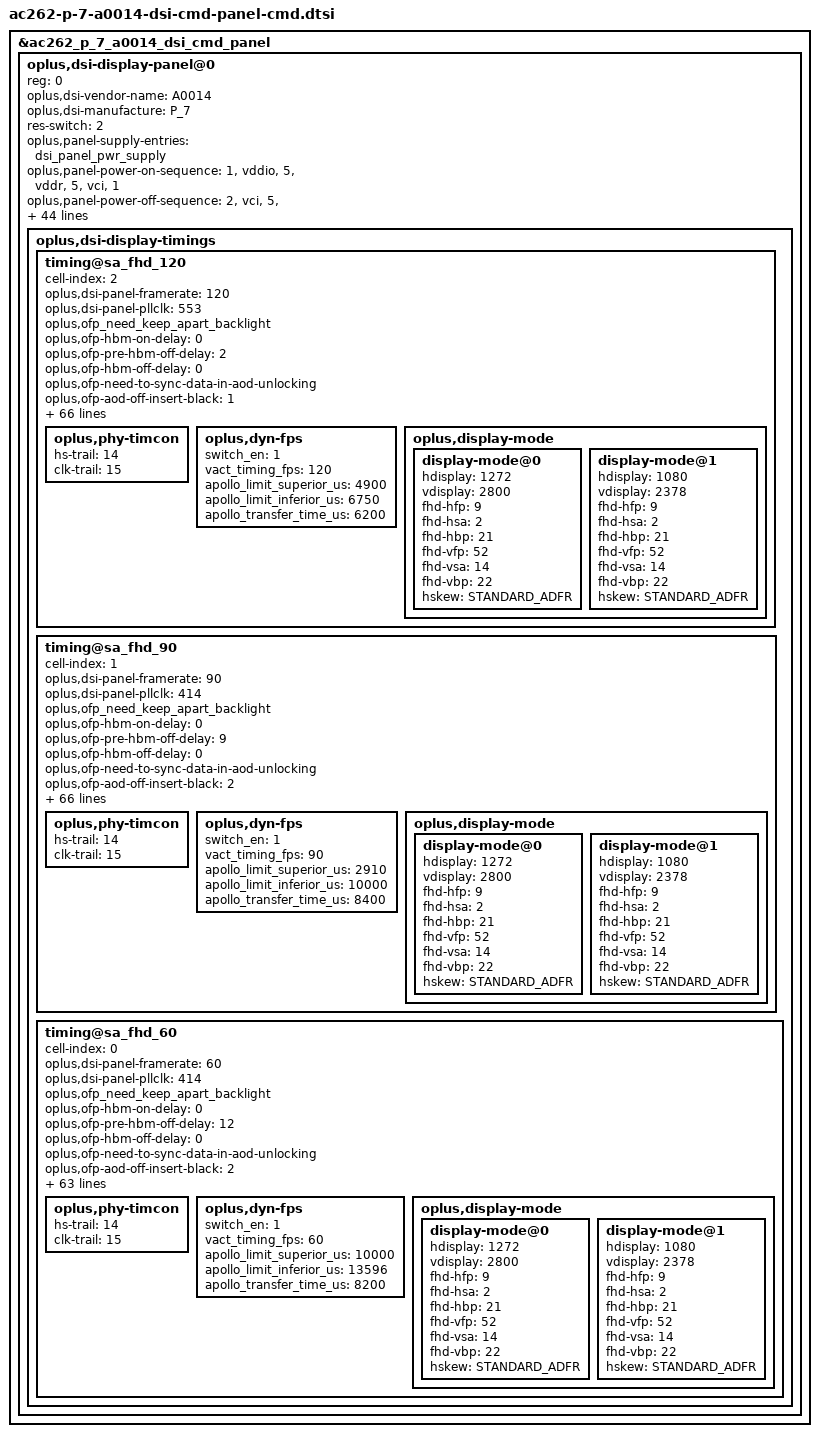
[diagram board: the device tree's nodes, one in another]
&ac262_p_7_a0014_dsi_cmd_panel {
	oplus,dsi-display-panel@0 {
		reg = <0>;
		oplus,dsi-vendor-name = "A0014";
		oplus,dsi-manufacture = "P_7";
		oplus,dsi-display-timings {
			timing@sa_fhd_120 {
				cell-index = <2>;
				oplus,dsi-panel-framerate = <120>;
				oplus,dsi-panel-pllclk = <553>;
				//oplus,merge-trig-offset = <333>;
				//oplus,cmd-null-pkt-en = <1>;
				//oplus,cmd-null-pkt-len = <0>;
				/* OPLUS_FEATURE_DISPLAY_ONSCREENFINGERPRINT */
				oplus,ofp_need_keep_apart_backlight;
				oplus,ofp-hbm-on-delay = <0>;
				oplus,ofp-pre-hbm-off-delay = <2>;
				oplus,ofp-hbm-off-delay = <0>;
				oplus,ofp-need-to-sync-data-in-aod-unlocking;
				oplus,ofp-aod-off-insert-black = <1>;
				oplus,ofp-aod-off-black-frame-total-time = <42>;
				#include "ac262-p-7-a0014-dsi-cmd-panel-common.dtsi"
				oplus,dsi-timing-switch-command = [
					39 00 00 00 00 00 02 2F 01
				];
				oplus,dsi-pwm-switch-1to3pul-command = [
				];
				oplus,dsi-pwm-switch-1to18pul-command = [
				];
				oplus,dsi-pwm-switch-18to3pul-command = [
				];
				oplus,dsi-pwm-switch-3to18pul-command = [
				];
				oplus,dsi-timing-switch-1pulse-command = [
				];
				oplus,dsi-pwm-switch-3to1pul-command = [
				];
				oplus,dsi-pwm-switch-18to1pul-command = [
				];
				oplus,dsi-on-command = [
					/* LHBM optimization */
					39 00 00 00 00 00 06 F0 55 AA 52 08 01
					15 00 00 00 00 00 02 6F 06
					39 00 00 00 00 00 05 DE 00 19 00 00
					39 00 00 00 00 00 06 F0 55 AA 52 08 08
					15 00 00 00 00 00 02 6F 30
					39 00 00 00 00 00 15 B2 00 00 39 55 23 14 29 F4 38 74 20 53 27 53 35 A3 21 12 2A A2
					15 00 00 00 00 00 02 6F 44
					39 00 00 00 00 00 15 B2 36 62 23 51 2B 61 33 81 36 91 24 90 2A 10 2F C0 32 10 33 B0
					15 00 00 00 00 00 02 6F 58
					39 00 00 00 00 00 0B B2 36 D0 3B D0 3F 20 00 1F 00 1F
					15 00 00 00 00 00 02 6F 00
					39 00 00 00 00 00 15 B2 00 08 00 46 00 84 00 E9 01 09 01 32 01 72 01 A5 01 E4 02 24
					15 00 00 00 00 00 02 6F 14
					39 00 00 00 00 00 15 B2 02 70 02 B2 02 F0 03 05 03 70 03 AA 03 E8 04 00 04 10 04 30
					15 00 00 00 00 00 02 6F 28
					39 00 00 00 00 00 09 B2 04 60 04 81 04 82 0F FF
					39 00 00 00 00 00 05 FF AA 55 A5 80
					39 00 00 00 00 00 02 6F 31
					39 00 00 00 00 00 03 F8 01 B9
					39 00 00 00 00 00 05 FF AA 55 A5 80
					39 00 00 00 00 00 02 6F 15
					39 00 00 00 00 00 03 F8 01 AE
					39 00 00 00 00 00 02 5A 01
					39 00 00 00 00 00 05 FF AA 55 A5 80
					39 00 00 00 00 00 02 6F 0A
					39 00 00 00 00 00 06 F6 70 70 70 70 70
					39 00 00 00 00 00 05 FF AA 55 A5 81
					39 00 00 00 00 00 02 6F 0D
					39 00 00 00 00 00 02 FB 80
					39 00 00 00 00 00 06 F0 55 AA 52 08 07
					39 00 00 00 00 00 0E B4 C0 80 80 80 80 40 80 80 80 80 80 45 80
					39 00 00 00 00 00 06 F0 55 AA 52 08 01
					39 00 00 00 00 00 02 E5 00
					39 00 00 00 00 00 05 FF AA 55 A5 81
					39 00 00 00 00 00 02 6F 0C
					39 00 00 00 00 00 02 FD 08
					39 00 00 00 00 00 02 6F 02
					39 00 00 00 00 00 02 F9 84
					39 00 00 00 00 00 02 6F 10
					39 00 00 00 00 00 02 FB 40
					39 00 00 00 00 00 05 FF AA 55 A5 80
					39 00 00 00 00 00 02 6F 48
					39 00 00 00 00 00 02 F2 00
					39 00 00 00 00 00 02 6F 16
					39 00 00 00 00 00 03 F4 02 74
					39 00 00 00 00 00 02 6F 42
					39 00 00 00 00 00 02 F4 00
					39 00 00 00 00 00 02 6F 49
					39 00 00 00 00 00 02 F2 10
					39 00 00 00 00 00 06 F0 55 AA 52 08 08
					39 00 00 00 00 00 0A 88 01 02 7C 0A 05 00 00 00 00
					39 00 00 00 00 00 05 FF AA 55 A5 81
					39 00 00 00 00 00 02 6F 05
					39 00 00 00 00 00 03 FE 3C 3C
					39 00 00 00 00 00 05 FF AA 55 A5 82
					39 00 00 00 00 00 02 6F 09
					39 00 00 00 00 00 02 F2 FF
					39 00 00 00 00 00 05 FF AA 55 A5 80
					39 00 00 00 00 00 02 6F 04
					39 00 00 00 00 00 02 F2 3C
					39 00 00 00 00 00 02 17 30
					39 00 00 00 00 00 02 2F 01
					39 00 00 00 00 00 03 5F 00 00
					39 00 00 00 00 00 02 35 00
					39 00 00 00 00 00 02 53 20
					39 00 00 00 00 00 05 2A 00 00 04 F7
					39 00 00 00 00 00 05 2B 00 00 0A EF
					39 00 00 00 00 00 03 90 03 43
					39 00 00 00 00 00 13 91 AB A8 00 10 C2 00 02 3E 01 A3 00 08 06 67 05 66 10 F0
					39 00 00 00 00 00 02 26 00
					39 00 00 00 00 00 06 F0 55 AA 52 08 08
					39 00 00 00 00 00 02 BE 03
					39 00 00 00 00 00 05 FF AA 55 A5 81
					39 00 00 00 00 00 02 6F 0B
					39 00 00 00 00 00 02 FD 04
					39 00 00 00 78 00 02 11 00
					39 00 00 00 00 00 02 29 00
				];
				oplus,dsi-aod-off-command = [
					39 00 00 40 00 00 02 38 00
					39 00 00 00 00 00 03 51 00 00
				];
				oplus,dsi-panel-aod-off-insert-black-command = [
					39 00 00 40 00 00 06 F0 55 AA 52 08 00
					39 00 00 40 00 00 02 C0 70
					39 00 00 40 00 00 06 F0 55 AA 52 08 01
					39 00 00 40 00 00 02 6F 01
					39 00 00 40 00 00 02 D2 11
					39 00 00 40 00 00 02 38 00
					39 00 00 00 00 00 03 51 00 00
				];
				oplus,dsi-lhbm-pressed-icon-on-command = [
					39 00 00 40 00 00 06 F0 55 AA 52 08 08
					39 00 00 40 00 00 02 6F 4A
					39 00 00 40 00 00 0D A9 02 00 DF 31 31 06 01 00 87 00 00 05
					39 00 00 40 00 00 06 F0 55 AA 52 08 04
					39 00 00 40 00 00 02 CB 37
					39 00 00 00 00 00 02 8B 10
					39 00 00 40 00 00 06 F0 55 AA 52 08 00
					39 00 00 40 00 00 02 6F 30
					39 00 00 40 00 00 02 DF 00
					39 00 00 40 00 00 02 6F 36
					39 00 00 40 00 00 02 DF 01
				];
				oplus,dsi-lhbm-pressed-icon-on-pwm-command = [
					39 00 00 40 00 00 06 F0 55 AA 52 08 08
					39 00 00 40 00 00 02 6F 4A
					39 00 00 40 00 00 0D A9 02 00 DF 31 31 16 01 00 87 00 00 25
					39 00 00 40 00 00 06 F0 55 AA 52 08 04
					39 00 00 40 00 00 02 CB 37
					39 00 00 00 00 00 02 8B 10
					39 00 00 40 00 00 06 F0 55 AA 52 08 00
					39 00 00 40 00 00 02 6F 30
					39 00 00 40 00 00 02 DF 00
					39 00 00 40 00 00 02 6F 36
					39 00 00 40 00 00 02 DF 01
				];
				oplus,dsi-adfr-min-fps-120hz-command = [
				];
				oplus,dsi-adfr-min-fps-60hz-command = [
				];
				oplus,dsi-adfr-min-fps-30hz-command = [
				];
				oplus,dsi-adfr-min-fps-20hz-command = [
				];
				oplus,dsi-adfr-min-fps-10hz-command = [
				];
				oplus,dsi-adfr-min-fps-5hz-command = [
				];
				oplus,dsi-adfr-min-fps-1hz-command = [
				];

				oplus,dsi-timing-switch-command-state = "dsi_hs_mode";
				oplus,dsi-pwm-switch-1to3pul-command-state = "dsi_hs_mode";
				oplus,dsi-pwm-switch-1to18pul-command-state = "dsi_hs_mode";
				oplus,dsi-pwm-switch-18to3pul-command-state = "dsi_hs_mode";
				oplus,dsi-pwm-switch-3to18pul-command-state = "dsi_hs_mode";
				oplus,dsi-timing-switch-1pulse-command-state = "dsi_hs_mode";
				oplus,dsi-pwm-switch-3to1pul-command-state = "dsi_hs_mode";
				oplus,dsi-pwm-switch-18to1pul-command-state = "dsi_hs_mode";
				oplus,dsi-on-command-state = "dsi_lp_mode";
				oplus,dsi-aod-off-command-state = "dsi_ls_mode";
				oplus,dsi-panel-aod-off-insert-black-command-state = "dsi_ls_mode";
				oplus,dsi-lhbm-pressed-icon-on-command-state = "dsi_hs_mode";
				oplus,dsi-lhbm-pressed-icon-on-pwm-command-state = "dsi_hs_mode";
				oplus,dsi-adfr-min-fps-120hz-command-state = "dsi_hs_mode";
				oplus,dsi-adfr-min-fps-60hz-command-state = "dsi_hs_mode";
				oplus,dsi-adfr-min-fps-30hz-command-state = "dsi_hs_mode";
				oplus,dsi-adfr-min-fps-20hz-command-state = "dsi_hs_mode";
				oplus,dsi-adfr-min-fps-10hz-command-state = "dsi_hs_mode";
				oplus,dsi-adfr-min-fps-5hz-command-state = "dsi_hs_mode";
				oplus,dsi-adfr-min-fps-1hz-command-state = "dsi_hs_mode";

				oplus,dsc-params-entries = <&dsc_params>;
				oplus,phy-timcon {
					hs-trail = <14>;
					clk-trail = <15>;
				};
				oplus,dyn-fps {
					switch_en = <1>;
					vact_timing_fps = <120>;
					apollo_limit_superior_us = <4900>;
					apollo_limit_inferior_us = <6750>;
					apollo_transfer_time_us = <6200>;
				};
				oplus,display-mode {
					display-mode@0 {
						hdisplay = <1272>;
						vdisplay = <2800>;
						fhd-hfp = <9>;
						fhd-hsa = <2>;
						fhd-hbp = <21>;
						fhd-vfp = <52>;
						fhd-vsa = <14>;
						fhd-vbp = <22>;
						hskew = <STANDARD_ADFR>;
					};
					display-mode@1 {
						hdisplay = <1080>;
						vdisplay = <2378>;
						fhd-hfp = <9>;
						fhd-hsa = <2>;
						fhd-hbp = <21>;
						fhd-vfp = <52>;
						fhd-vsa = <14>;
						fhd-vbp = <22>;
						hskew = <STANDARD_ADFR>;
					};
				};
			};

			timing@sa_fhd_90 {
				cell-index = <1>;
				oplus,dsi-panel-framerate = <90>;
				oplus,dsi-panel-pllclk = <414>;
				/* OPLUS_FEATURE_DISPLAY_ONSCREENFINGERPRINT */
				oplus,ofp_need_keep_apart_backlight;
				oplus,ofp-hbm-on-delay = <0>;
				oplus,ofp-pre-hbm-off-delay = <9>;
				oplus,ofp-hbm-off-delay = <0>;
				oplus,ofp-need-to-sync-data-in-aod-unlocking;
				oplus,ofp-aod-off-insert-black = <2>;
				oplus,ofp-aod-off-black-frame-total-time = <45>;
				#include "ac262-p-7-a0014-dsi-cmd-panel-common.dtsi"
				oplus,dsi-timing-switch-command = [
					39 00 00 00 00 00 02 2F 02
				];
				oplus,dsi-pwm-switch-1to3pul-command = [
				];
				oplus,dsi-pwm-switch-1to18pul-command = [
				];
				oplus,dsi-pwm-switch-18to3pul-command = [
				];
				oplus,dsi-pwm-switch-3to18pul-command = [
				];
				oplus,dsi-timing-switch-1pulse-command = [
				];
				oplus,dsi-pwm-switch-3to1pul-command = [
				];
				oplus,dsi-pwm-switch-18to1pul-command = [
				];
				oplus,dsi-on-command = [
					/* LHBM optimization */
					39 00 00 00 00 00 06 F0 55 AA 52 08 01
					15 00 00 00 00 00 02 6F 06
					39 00 00 00 00 00 05 DE 00 19 00 00
					39 00 00 00 00 00 06 F0 55 AA 52 08 08
					15 00 00 00 00 00 02 6F 30
					39 00 00 00 00 00 15 B2 00 00 39 55 23 14 29 F4 38 74 20 53 27 53 35 A3 21 12 2A A2
					15 00 00 00 00 00 02 6F 44
					39 00 00 00 00 00 15 B2 36 62 23 51 2B 61 33 81 36 91 24 90 2A 10 2F C0 32 10 33 B0
					15 00 00 00 00 00 02 6F 58
					39 00 00 00 00 00 0B B2 36 D0 3B D0 3F 20 00 1F 00 1F
					15 00 00 00 00 00 02 6F 00
					39 00 00 00 00 00 15 B2 00 08 00 46 00 84 00 E9 01 09 01 32 01 72 01 A5 01 E4 02 24
					15 00 00 00 00 00 02 6F 14
					39 00 00 00 00 00 15 B2 02 70 02 B2 02 F0 03 05 03 70 03 AA 03 E8 04 00 04 10 04 30
					15 00 00 00 00 00 02 6F 28
					39 00 00 00 00 00 09 B2 04 60 04 81 04 82 0F FF
					39 00 00 00 00 00 05 FF AA 55 A5 80
					39 00 00 00 00 00 02 6F 31
					39 00 00 00 00 00 03 F8 01 B9
					39 00 00 00 00 00 05 FF AA 55 A5 80
					39 00 00 00 00 00 02 6F 15
					39 00 00 00 00 00 03 F8 01 AE
					39 00 00 00 00 00 02 5A 01
					39 00 00 00 00 00 05 FF AA 55 A5 80
					39 00 00 00 00 00 02 6F 0A
					39 00 00 00 00 00 06 F6 70 70 70 70 70
					39 00 00 00 00 00 05 FF AA 55 A5 81
					39 00 00 00 00 00 02 6F 0D
					39 00 00 00 00 00 02 FB 80
					39 00 00 00 00 00 06 F0 55 AA 52 08 07
					39 00 00 00 00 00 0E B4 C0 80 80 80 80 40 80 80 80 80 80 45 80
					39 00 00 00 00 00 06 F0 55 AA 52 08 01
					39 00 00 00 00 00 02 E5 00
					39 00 00 00 00 00 05 FF AA 55 A5 81
					39 00 00 00 00 00 02 6F 0C
					39 00 00 00 00 00 02 FD 08
					39 00 00 00 00 00 02 6F 02
					39 00 00 00 00 00 02 F9 84
					39 00 00 00 00 00 02 6F 10
					39 00 00 00 00 00 02 FB 40
					39 00 00 00 00 00 05 FF AA 55 A5 80
					39 00 00 00 00 00 02 6F 48
					39 00 00 00 00 00 02 F2 00
					39 00 00 00 00 00 02 6F 16
					39 00 00 00 00 00 03 F4 02 74
					39 00 00 00 00 00 02 6F 42
					39 00 00 00 00 00 02 F4 00
					39 00 00 00 00 00 02 6F 49
					39 00 00 00 00 00 02 F2 10
					39 00 00 00 00 00 06 F0 55 AA 52 08 08
					39 00 00 00 00 00 0A 88 01 02 7C 0A 05 00 00 00 00
					39 00 00 00 00 00 05 FF AA 55 A5 81
					39 00 00 00 00 00 02 6F 05
					39 00 00 00 00 00 03 FE 3C 3C
					39 00 00 00 00 00 05 FF AA 55 A5 82
					39 00 00 00 00 00 02 6F 09
					39 00 00 00 00 00 02 F2 FF
					39 00 00 00 00 00 05 FF AA 55 A5 80
					39 00 00 00 00 00 02 6F 04
					39 00 00 00 00 00 02 F2 3C
					39 00 00 00 00 00 02 17 30
					39 00 00 00 00 00 02 2F 02
					39 00 00 00 00 00 03 5F 00 00
					39 00 00 00 00 00 02 35 00
					39 00 00 00 00 00 02 53 20
					39 00 00 00 00 00 05 2A 00 00 04 F7
					39 00 00 00 00 00 05 2B 00 00 0A EF
					39 00 00 00 00 00 03 90 03 43
					39 00 00 00 00 00 13 91 AB A8 00 10 C2 00 02 3E 01 A3 00 08 06 67 05 66 10 F0
					39 00 00 00 00 00 02 26 00
					39 00 00 00 00 00 06 F0 55 AA 52 08 08
					39 00 00 00 00 00 02 BE 03
					39 00 00 00 00 00 05 FF AA 55 A5 81
					39 00 00 00 00 00 02 6F 0B
					39 00 00 00 00 00 02 FD 04
					39 00 00 00 78 00 02 11 00
					39 00 00 00 00 00 02 29 00
				];
				oplus,dsi-aod-off-command = [
					39 00 00 40 00 00 02 38 00
					39 00 00 00 00 00 03 51 00 00
				];
				oplus,dsi-panel-aod-off-insert-black-command = [
					39 00 00 40 00 00 06 F0 55 AA 52 08 00
					39 00 00 40 00 00 02 C0 70
					39 00 00 40 00 00 06 F0 55 AA 52 08 01
					39 00 00 40 00 00 02 6F 01
					39 00 00 40 00 00 02 D2 11
					39 00 00 40 00 00 02 38 00
					39 00 00 00 00 00 03 51 00 00
				];
				oplus,dsi-lhbm-pressed-icon-on-command = [
					39 00 00 40 00 00 06 F0 55 AA 52 08 08
					39 00 00 40 00 00 02 6F 4A
					39 00 00 40 00 00 0D A9 02 00 DF 31 31 06 01 00 87 00 00 05
					39 00 00 40 00 00 06 F0 55 AA 52 08 04
					39 00 00 40 00 00 02 CB 37
					39 00 00 00 00 00 02 8B 10
				];
				oplus,dsi-lhbm-pressed-icon-on-pwm-command = [
					39 00 00 40 00 00 06 F0 55 AA 52 08 08
					39 00 00 40 00 00 02 6F 4A
					39 00 00 40 00 00 0D A9 02 00 DF 31 31 16 01 00 87 00 00 25
					39 00 00 40 00 00 06 F0 55 AA 52 08 04
					39 00 00 40 00 00 02 CB 37
					39 00 00 00 00 00 02 8B 10
				];
				oplus,dsi-adfr-min-fps-90hz-command = [
				];
				oplus,dsi-adfr-min-fps-45hz-command = [
				];
				oplus,dsi-adfr-min-fps-30hz-command = [
				];
				oplus,dsi-adfr-min-fps-15hz-command = [
				];
				oplus,dsi-adfr-min-fps-10hz-command = [
				];
				oplus,dsi-adfr-min-fps-5hz-command = [
				];
				oplus,dsi-adfr-min-fps-1hz-command = [
				];

				oplus,dsi-timing-switch-command-state = "dsi_hs_mode";
				oplus,dsi-pwm-switch-1to3pul-command-state = "dsi_hs_mode";
				oplus,dsi-pwm-switch-1to18pul-command-state = "dsi_hs_mode";
				oplus,dsi-pwm-switch-18to3pul-command-state = "dsi_hs_mode";
				oplus,dsi-pwm-switch-3to18pul-command-state = "dsi_hs_mode";
				oplus,dsi-timing-switch-1pulse-command-state = "dsi_hs_mode";
				oplus,dsi-pwm-switch-3to1pul-command-state = "dsi_hs_mode";
				oplus,dsi-pwm-switch-18to1pul-command-state = "dsi_hs_mode";
				oplus,dsi-on-command-state = "dsi_lp_mode";
				oplus,dsi-aod-off-command-state = "dsi_ls_mode";
				oplus,dsi-panel-aod-off-insert-black-command-state = "dsi_ls_mode";
				oplus,dsi-lhbm-pressed-icon-on-command-state = "dsi_hs_mode";
				oplus,dsi-lhbm-pressed-icon-on-pwm-command-state = "dsi_hs_mode";
				oplus,dsi-adfr-min-fps-90hz-command-state = "dsi_hs_mode";
				oplus,dsi-adfr-min-fps-45hz-command-state = "dsi_hs_mode";
				oplus,dsi-adfr-min-fps-30hz-command-state = "dsi_hs_mode";
				oplus,dsi-adfr-min-fps-15hz-command-state = "dsi_hs_mode";
				oplus,dsi-adfr-min-fps-10hz-command-state = "dsi_hs_mode";
				oplus,dsi-adfr-min-fps-5hz-command-state = "dsi_hs_mode";
				oplus,dsi-adfr-min-fps-1hz-command-state = "dsi_hs_mode";

				oplus,dsc-params-entries = <&dsc_params>;
				oplus,phy-timcon {
					hs-trail = <14>;
					clk-trail = <15>;
				};
				oplus,dyn-fps {
					switch_en = <1>;
					vact_timing_fps = <90>;
					apollo_limit_superior_us = <2910>;
					apollo_limit_inferior_us = <10000>;
					apollo_transfer_time_us = <8400>;
				};
				oplus,display-mode {
					display-mode@0 {
						hdisplay = <1272>;
						vdisplay = <2800>;
						fhd-hfp = <9>;
						fhd-hsa = <2>;
						fhd-hbp = <21>;
						fhd-vfp = <52>;
						fhd-vsa = <14>;
						fhd-vbp = <22>;
						hskew = <STANDARD_ADFR>;
					};
					display-mode@1 {
						hdisplay = <1080>;
						vdisplay = <2378>;
						fhd-hfp = <9>;
						fhd-hsa = <2>;
						fhd-hbp = <21>;
						fhd-vfp = <52>;
						fhd-vsa = <14>;
						fhd-vbp = <22>;
						hskew = <STANDARD_ADFR>;
					};
				};
			};

			timing@sa_fhd_60 {
				cell-index = <0>;
				oplus,dsi-panel-framerate = <60>;
				oplus,dsi-panel-pllclk = <414>;
				/* OPLUS_FEATURE_DISPLAY_ONSCREENFINGERPRINT */
				oplus,ofp_need_keep_apart_backlight;
				oplus,ofp-hbm-on-delay = <0>;
				oplus,ofp-pre-hbm-off-delay = <12>;
				oplus,ofp-hbm-off-delay = <0>;
				oplus,ofp-need-to-sync-data-in-aod-unlocking;
				oplus,ofp-aod-off-insert-black = <2>;
				oplus,ofp-aod-off-black-frame-total-time = <59>;
				#include "ac262-p-7-a0014-dsi-cmd-panel-common.dtsi"
				oplus,dsi-timing-switch-command = [
					39 00 00 00 00 00 02 2F 03
				];
				oplus,dsi-pwm-switch-1to3pul-command = [
				];
				oplus,dsi-pwm-switch-1to18pul-command = [
				];
				oplus,dsi-pwm-switch-18to3pul-command = [
				];
				oplus,dsi-pwm-switch-3to18pul-command = [
				];
				oplus,dsi-timing-switch-1pulse-command = [
				];
				oplus,dsi-pwm-switch-3to1pul-command = [
				];
				oplus,dsi-pwm-switch-18to1pul-command = [
				];
				oplus,dsi-on-command = [
					/* LHBM optimization */
					39 00 00 00 00 00 06 F0 55 AA 52 08 01
					15 00 00 00 00 00 02 6F 06
					39 00 00 00 00 00 05 DE 00 19 00 00
					39 00 00 00 00 00 06 F0 55 AA 52 08 08
					15 00 00 00 00 00 02 6F 30
					39 00 00 00 00 00 15 B2 00 00 39 55 23 14 29 F4 38 74 20 53 27 53 35 A3 21 12 2A A2
					15 00 00 00 00 00 02 6F 44
					39 00 00 00 00 00 15 B2 36 62 23 51 2B 61 33 81 36 91 24 90 2A 10 2F C0 32 10 33 B0
					15 00 00 00 00 00 02 6F 58
					39 00 00 00 00 00 0B B2 36 D0 3B D0 3F 20 00 1F 00 1F
					15 00 00 00 00 00 02 6F 00
					39 00 00 00 00 00 15 B2 00 08 00 46 00 84 00 E9 01 09 01 32 01 72 01 A5 01 E4 02 24
					15 00 00 00 00 00 02 6F 14
					39 00 00 00 00 00 15 B2 02 70 02 B2 02 F0 03 05 03 70 03 AA 03 E8 04 00 04 10 04 30
					15 00 00 00 00 00 02 6F 28
					39 00 00 00 00 00 09 B2 04 60 04 81 04 82 0F FF
					39 00 00 00 00 00 05 FF AA 55 A5 80
					39 00 00 00 00 00 02 6F 31
					39 00 00 00 00 00 03 F8 01 B9
					39 00 00 00 00 00 05 FF AA 55 A5 80
					39 00 00 00 00 00 02 6F 15
					39 00 00 00 00 00 03 F8 01 AE
					39 00 00 00 00 00 02 5A 01
					39 00 00 00 00 00 05 FF AA 55 A5 80
					39 00 00 00 00 00 02 6F 0A
					39 00 00 00 00 00 06 F6 70 70 70 70 70
					39 00 00 00 00 00 05 FF AA 55 A5 81
					39 00 00 00 00 00 02 6F 0D
					39 00 00 00 00 00 02 FB 80
					39 00 00 00 00 00 06 F0 55 AA 52 08 07
					39 00 00 00 00 00 0E B4 C0 80 80 80 80 40 80 80 80 80 80 45 80
					39 00 00 00 00 00 06 F0 55 AA 52 08 01
					39 00 00 00 00 00 02 E5 00
					39 00 00 00 00 00 05 FF AA 55 A5 81
					39 00 00 00 00 00 02 6F 0C
					39 00 00 00 00 00 02 FD 08
					39 00 00 00 00 00 02 6F 02
					39 00 00 00 00 00 02 F9 84
					39 00 00 00 00 00 02 6F 10
					39 00 00 00 00 00 02 FB 40
					39 00 00 00 00 00 05 FF AA 55 A5 80
					39 00 00 00 00 00 02 6F 48
					39 00 00 00 00 00 02 F2 00
					39 00 00 00 00 00 02 6F 16
					39 00 00 00 00 00 03 F4 02 74
					39 00 00 00 00 00 02 6F 42
					39 00 00 00 00 00 02 F4 00
					39 00 00 00 00 00 02 6F 49
					39 00 00 00 00 00 02 F2 10
					39 00 00 00 00 00 06 F0 55 AA 52 08 08
					39 00 00 00 00 00 0A 88 01 02 7C 0A 05 00 00 00 00
					39 00 00 00 00 00 05 FF AA 55 A5 81
					39 00 00 00 00 00 02 6F 05
					39 00 00 00 00 00 03 FE 3C 3C
					39 00 00 00 00 00 05 FF AA 55 A5 82
					39 00 00 00 00 00 02 6F 09
					39 00 00 00 00 00 02 F2 FF
					39 00 00 00 00 00 05 FF AA 55 A5 80
					39 00 00 00 00 00 02 6F 04
					39 00 00 00 00 00 02 F2 3C
					39 00 00 00 00 00 02 17 30
					39 00 00 00 00 00 02 2F 03
					39 00 00 00 00 00 03 5F 00 00
					39 00 00 00 00 00 02 35 00
					39 00 00 00 00 00 02 53 20
					39 00 00 00 00 00 05 2A 00 00 04 F7
					39 00 00 00 00 00 05 2B 00 00 0A EF
					39 00 00 00 00 00 03 90 03 43
					39 00 00 00 00 00 13 91 AB A8 00 10 C2 00 02 3E 01 A3 00 08 06 67 05 66 10 F0
					39 00 00 00 00 00 02 26 00
					39 00 00 00 00 00 06 F0 55 AA 52 08 08
					39 00 00 00 00 00 02 BE 03
					39 00 00 00 00 00 05 FF AA 55 A5 81
					39 00 00 00 00 00 02 6F 0B
					39 00 00 00 00 00 02 FD 04
					39 00 00 00 78 00 02 11 00
					39 00 00 00 00 00 02 29 00
				];
				oplus,dsi-aod-off-command = [
					39 00 00 40 00 00 02 38 00
					39 00 00 00 00 00 03 51 00 00
				];
				oplus,dsi-panel-aod-off-insert-black-command = [
					39 00 00 40 00 00 06 F0 55 AA 52 08 00
					39 00 00 40 00 00 02 C0 70
					39 00 00 40 00 00 06 F0 55 AA 52 08 01
					39 00 00 40 00 00 02 6F 01
					39 00 00 40 00 00 02 D2 11
					39 00 00 40 00 00 02 38 00
					39 00 00 00 00 00 03 51 00 00
				];
				oplus,dsi-lhbm-pressed-icon-on-command = [
					39 00 00 40 00 00 06 F0 55 AA 52 08 08
					39 00 00 40 00 00 02 6F 4A
					39 00 00 40 00 00 0D A9 02 00 DF 31 31 06 01 00 87 00 00 05
					39 00 00 40 00 00 06 F0 55 AA 52 08 04
					39 00 00 40 00 00 02 CB 37
					39 00 00 00 00 00 02 8B 10
					39 00 00 40 00 00 06 F0 55 AA 52 08 00
					39 00 00 40 00 00 02 6F 30
					39 00 00 40 00 00 02 DF 02
					39 00 00 40 00 00 02 6F 36
					39 00 00 40 00 00 02 DF 03
				];
				oplus,dsi-lhbm-pressed-icon-on-pwm-command = [
					39 00 00 40 00 00 06 F0 55 AA 52 08 08
					39 00 00 40 00 00 02 6F 4A
					39 00 00 40 00 00 0D A9 02 00 DF 31 31 16 01 00 87 00 00 25
					39 00 00 40 00 00 06 F0 55 AA 52 08 04
					39 00 00 40 00 00 02 CB 37
					39 00 00 00 00 00 02 8B 10
					39 00 00 40 00 00 06 F0 55 AA 52 08 00
					39 00 00 40 00 00 02 6F 30
					39 00 00 40 00 00 02 DF 02
					39 00 00 40 00 00 02 6F 36
					39 00 00 40 00 00 02 DF 03
				];
				oplus,dsi-adfr-min-fps-60hz-command = [
				];
				oplus,dsi-adfr-min-fps-30hz-command = [
				];
				oplus,dsi-adfr-min-fps-20hz-command = [
				];
				oplus,dsi-adfr-min-fps-10hz-command = [
				];
				oplus,dsi-adfr-min-fps-5hz-command = [
				];
				oplus,dsi-adfr-min-fps-1hz-command = [
				];

				oplus,dsi-timing-switch-command-state = "dsi_hs_mode";
				oplus,dsi-pwm-switch-1to3pul-command-state = "dsi_hs_mode";
				oplus,dsi-pwm-switch-1to18pul-command-state = "dsi_hs_mode";
				oplus,dsi-pwm-switch-18to3pul-command-state = "dsi_hs_mode";
				oplus,dsi-pwm-switch-3to18pul-command-state = "dsi_hs_mode";
				oplus,dsi-timing-switch-1pulse-command-state = "dsi_hs_mode";
				oplus,dsi-pwm-switch-3to1pul-command-state = "dsi_hs_mode";
				oplus,dsi-pwm-switch-18to1pul-command-state = "dsi_hs_mode";
				oplus,dsi-on-command-state = "dsi_lp_mode";
				oplus,dsi-aod-off-command-state = "dsi_ls_mode";
				oplus,dsi-panel-aod-off-insert-black-command-state = "dsi_ls_mode";
				oplus,dsi-lhbm-pressed-icon-on-command-state = "dsi_hs_mode";
				oplus,dsi-lhbm-pressed-icon-on-pwm-command-state = "dsi_hs_mode";
				oplus,dsi-adfr-min-fps-60hz-command-state = "dsi_hs_mode";
				oplus,dsi-adfr-min-fps-30hz-command-state = "dsi_hs_mode";
				oplus,dsi-adfr-min-fps-20hz-command-state = "dsi_hs_mode";
				oplus,dsi-adfr-min-fps-10hz-command-state = "dsi_hs_mode";
				oplus,dsi-adfr-min-fps-5hz-command-state = "dsi_hs_mode";
				oplus,dsi-adfr-min-fps-1hz-command-state = "dsi_hs_mode";

				oplus,dsc-params-entries = <&dsc_params>;
				oplus,phy-timcon {
					hs-trail = <14>;
					clk-trail = <15>;
				};
				oplus,dyn-fps {
					switch_en = <1>;
					vact_timing_fps = <60>;
					apollo_limit_superior_us = <10000>;
					apollo_limit_inferior_us = <13596>;
					apollo_transfer_time_us = <8200>;
				};
				oplus,display-mode {
					display-mode@0 {
						hdisplay = <1272>;
						vdisplay = <2800>;
						fhd-hfp = <9>;
						fhd-hsa = <2>;
						fhd-hbp = <21>;
						fhd-vfp = <52>;
						fhd-vsa = <14>;
						fhd-vbp = <22>;
						hskew = <STANDARD_ADFR>;
					};
					display-mode@1 {
						hdisplay = <1080>;
						vdisplay = <2378>;
						fhd-hfp = <9>;
						fhd-hsa = <2>;
						fhd-hbp = <21>;
						fhd-vfp = <52>;
						fhd-vsa = <14>;
						fhd-vbp = <22>;
						hskew = <STANDARD_ADFR>;
					};
				};
			};
		};
	};
};

&ac262_p_7_a0014_dsi_cmd_panel {
	oplus,dsi-display-panel@0 {
		res-switch = <2>;
		/* Hardware config */
		oplus,panel-supply-entries = <&dsi_panel_pwr_supply>;
		oplus,panel-power-on-sequence = "1", "vddio", "5", "vddr", "5", "vci", "1";
		oplus,panel-power-off-sequence = "2", "vci", "5", "vddr", "5", "vddio", "1";
		reset-gpios = <&pio 41 0>;
		oplus,panel-reset-sequence = <2 10>, <1 1>, <0 1>, <1 20>;
		/* Panel config */
		oplus,dsi-serial-number-enabled=<1>;
		oplus,dsi-serial-number-switch-page;
		oplus,dsi-serial-number-index= <0>;
		oplus,dsi-serial-number-switch-page-command = <0xF0 0x55 0xAA 0x52 0x08 0x01>;
		oplus,dsi-serial-number-default-switch-page-command = <0xF0 0x55 0xAA 0x52 0x08 0x00>;
		oplus,dsi-serial-number-reg= <0xD7>;
		oplus,dsi-serial-number-read-count= <7>;
		oplus,dsi-serial-number-year-offset= <10>;
		oplus,mode-switch-h2l-delay;
		oplus,backlight-check-disable;
		/* demura */
		oplus,demura-dbv-enable;
		oplus,demura-dbv-cfg = <1153 4095>;
		/*color*/
		oplus,color-vivid-status;
		oplus,color-srgb-status;
		// oplus,color-softiris-status;
		// oplus,color-dual-panel-status;
		oplus,color-dual-brightness-status;
		oplus,color-oplus-calibrate-status;
		// oplus,color-samsung-status;
		oplus,color-loading-status;
		//oplus,color-2nit-status;
		// oplus,color-nature-profession-status;
		/* ESD */
		oplus,cust-esd-check = <0>; //both check TE and reg
		oplus,esd-check-enable = <1>;
		oplus,esd_check_cmd = [
			0A
			91
		];
		oplus,esd_check_count = [
			01
			01
		];
		oplus,esd_check_value = [
			9C
			AB
		];
		oplus,esd_check_mask = [
			FF
			FF
		];
		/* ext_params */
		oplus,panel-type = <2>;
		oplus,keep_ulps = <1>;
		oplus,lane-swap-en = <0>;
		oplus,lane-swap = <
			MIPITX_PHY_LANE_0 MIPITX_PHY_LANE_1 MIPITX_PHY_LANE_3 MIPITX_PHY_LANE_2 MIPITX_PHY_LANE_CK MIPITX_PHY_LANE_RX
			MIPITX_PHY_LANE_0 MIPITX_PHY_LANE_1 MIPITX_PHY_LANE_3 MIPITX_PHY_LANE_2 MIPITX_PHY_LANE_CK MIPITX_PHY_LANE_RX
		>;
		oplus,lcm-color-mode = <MTK_DRM_COLOR_MODE_DISPLAY_P3>;
		oplus,output-mode = <MTK_PANEL_DSC_SINGLE_PORT>;
		oplus,panel-bpp = <10>;
		oplus,physical-width-um = <71740>;
		oplus,physical-height-um = <157920>;

		/*adfr config*/
		//oplus-adfr-config = <0x201>;
		//oplus-adfr-test-te-gpios = <&pio 42 0>;

		/* OFP config */
		oplus,ofp-fp-type = <0x10>;
		oplus,ofp-fp-local-hbm-calibration;
		oplus,ofp-longrui-aod-config = <0x06>;
		oplus,ofp-need-aod-off-insert-black-frame;
		/*pwm config*/
		//oplus,pwm-turbo-support = <1>;
		//oplus,pwm-switch-backlight-threshold = <1162>;
		//oplus,pwm-aid-switch-enable;
		//oplus,pwm-onepulse-support = <1>;
		//oplus,pwm-onepulse-enabled = <0>;
		//oplus,pwm-turbo-wait-te = <1>;
	};
};
